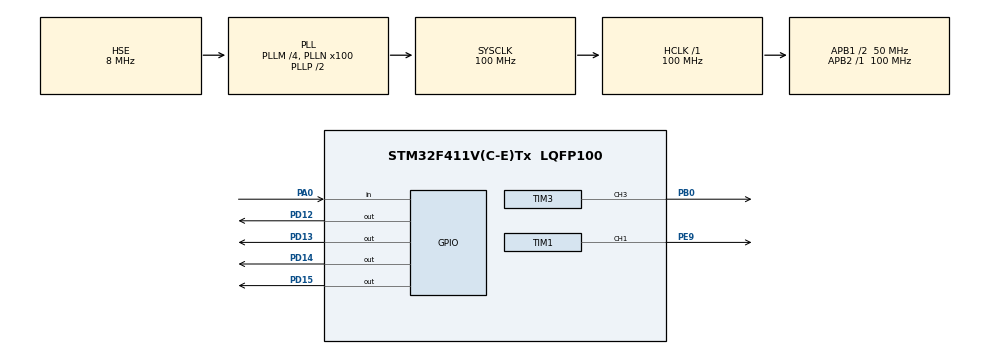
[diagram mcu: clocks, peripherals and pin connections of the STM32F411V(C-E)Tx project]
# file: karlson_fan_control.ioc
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Mcu.Family=STM32F4
Mcu.Name=STM32F411V(C-E)Tx
Mcu.Package=LQFP100
NVIC.PriorityGroup=NVIC_PRIORITYGROUP_4
NVIC.TIM1_BRK_TIM9_IRQn=true\:0\:0\:false\:false\:true\:true\:true
NVIC.TIM3_IRQn=true\:0\:0\:false\:false\:true\:true\:true
PA0-WKUP.GPIO_PuPd=GPIO_NOPULL
PA0-WKUP.Signal=GPIO_Input
PA13.Mode=Serial_Wire
PA13.Signal=SYS_JTMS-SWDIO
PA14.Mode=Serial_Wire
PA14.Signal=SYS_JTCK-SWCLK
PB0.GPIO_PuPd=GPIO_NOPULL
PB0.GPIO_Speed=GPIO_SPEED_FREQ_VERY_HIGH
PB0.Signal=S_TIM3_CH3
PD12.GPIO_Speed=GPIO_SPEED_FREQ_HIGH
PD12.Signal=GPIO_Output
PD13.GPIO_Speed=GPIO_SPEED_FREQ_HIGH
PD13.Signal=GPIO_Output
PD14.GPIO_Speed=GPIO_SPEED_FREQ_HIGH
PD14.Signal=GPIO_Output
PD15.GPIO_Speed=GPIO_SPEED_FREQ_HIGH
PD15.Signal=GPIO_Output
PE9.Signal=S_TIM1_CH1
PH0\ -\ OSC_IN.Mode=HSE-External-Oscillator
PH0\ -\ OSC_IN.Signal=RCC_OSC_IN
PH1\ -\ OSC_OUT.Mode=HSE-External-Oscillator
PH1\ -\ OSC_OUT.Signal=RCC_OSC_OUT
ProjectManager.HeapSize=0x200
ProjectManager.StackSize=0x400
ProjectManager.TargetToolchain=TrueSTUDIO
RCC.48MHZClocksFreq_Value=50000000
RCC.AHBFreq_Value=100000000
RCC.APB1CLKDivider=RCC_HCLK_DIV2
RCC.APB1Freq_Value=50000000
RCC.APB1TimFreq_Value=100000000
RCC.APB2Freq_Value=100000000
RCC.APB2TimFreq_Value=100000000
RCC.CortexFreq_Value=100000000
RCC.HCLKFreq_Value=100000000
RCC.HSE_VALUE=8000000
RCC.HSI_VALUE=16000000
RCC.LSE_VALUE=32768
RCC.PLLM=4
RCC.PLLN=100
RCC.PLLSourceVirtual=RCC_PLLSOURCE_HSE
RCC.SYSCLKFreq_VALUE=100000000
RCC.SYSCLKSource=RCC_SYSCLKSOURCE_PLLCLK
RCC.VCOOutputFreq_Value=200000000
SH.S_TIM1_CH1.0=TIM1_CH1,PWM Generation1 CH1
SH.S_TIM3_CH3.0=TIM3_CH3,PWM Generation3 CH3
TIM1.Channel-PWM\ Generation1\ CH1=TIM_CHANNEL_1
TIM1.OCMode_PWM-PWM\ Generation1\ CH1=TIM_OCMODE_PWM1
TIM1.OCPolarity_1=TIM_OCPOLARITY_HIGH
TIM1.Period=65535
TIM1.Prescaler=0
TIM1.Pulse-PWM\ Generation1\ CH1=0
TIM3.Channel-PWM\ Generation3\ CH3=TIM_CHANNEL_3
TIM3.OCMode_PWM-PWM\ Generation3\ CH3=TIM_OCMODE_PWM2
TIM3.Period=0
TIM3.Prescaler=0
VP_TIM3_VS_ClockSourceINT.Mode=Internal
board=custom

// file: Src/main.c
/* USER CODE BEGIN Header */
/**
  ******************************************************************************
  * @file           : main.c
  * @brief          : Main program body
  ******************************************************************************
  * @attention
  *
  * <h2><center>&copy; Copyright (c) 2019 STMicroelectronics.
  * All rights reserved.</center></h2>
  *
  * This software component is licensed by ST under BSD 3-Clause license,
  * the "License"; You may not use this file except in compliance with the
  * License. You may obtain a copy of the License at:
  *                        opensource.org/licenses/BSD-3-Clause
  *
  ******************************************************************************
  */
/* USER CODE END Header */

#include "main.h"

TIM_HandleTypeDef htim1;
TIM_HandleTypeDef htim3;

void SystemClock_Config(void);
static void MX_GPIO_Init(void);
static void MX_TIM3_Init(void);
static void MX_TIM1_Init(void);

int main(void)
{
  /* USER CODE BEGIN 1 */
	uint32_t i,d;
  /* USER CODE END 1 */

  /* MCU Configuration--------------------------------------------------------*/

  /* Reset of all peripherals, Initializes the Flash interface and the Systick. */
  HAL_Init();

  /* Configure the system clock */
  SystemClock_Config();

  /* Initialize all configured peripherals */
  MX_GPIO_Init();
  MX_TIM3_Init();
  MX_TIM1_Init();
  /* USER CODE BEGIN 2 */
  HAL_TIM_PWM_Start_IT(&htim3, TIM_CHANNEL_3);
  HAL_TIM_PWM_Start_IT(&htim1, TIM_CHANNEL_1);
  /* USER CODE END 2 */

  /* Infinite loop */
  while (1)
  {

    /* USER CODE BEGIN 3 */
	  // 10% duty cycle:     pulse_length = ((1999 + 1) * 10) / 100 - 1 = 199
	  // 20% duty cycle:     pulse_length = ((1999 + 1) * 20) / 100 - 1 = 399
	  // 30% duty cycle:     pulse_length = ((1999 + 1) * 30) / 100 - 1 = 599
	  // 40% duty cycle:     pulse_length = ((1999 + 1) * 40) / 100 - 1 = 799
	  // 50% duty cycle:     pulse_length = ((1999 + 1) * 50) / 100 - 1 = 999
	  // 60% duty cycle:     pulse_length = ((1999 + 1) * 60) / 100 - 1 = 1199
	  // 70% duty cycle:     pulse_length = ((1999 + 1) * 70) / 100 - 1 = 1399
	  // 80% duty cycle:     pulse_length = ((1999 + 1) * 80) / 100 - 1 = 1599
	  // 90% duty cycle:     pulse_length = ((1999 + 1) * 90) / 100 - 1 = 1799
	  // 100% duty cycle:     pulse_length = ((1999 + 1) * 100) / 100 - 1 = 1999

	  if (HAL_GPIO_ReadPin (GPIOA, GPIO_PIN_0))
	  {
		  /*HAL_Delay(50);*/
		  HAL_GPIO_WritePin(GPIOD, GPIO_PIN_12, GPIO_PIN_RESET);
		  HAL_GPIO_WritePin(GPIOD, GPIO_PIN_15, GPIO_PIN_SET);
		  TIM3->CCR3 = 3999; // PB0
		  // TIM1->CCR1 = 1999;  PE9
		  // __HAL_TIM_SET_COMPARE(&htim1, TIM_CHANNEL_1, 65535);
	  }
	  else
	  {
		  HAL_GPIO_WritePin(GPIOD, GPIO_PIN_12, GPIO_PIN_SET);
		  HAL_GPIO_WritePin(GPIOD, GPIO_PIN_15, GPIO_PIN_RESET);
		  TIM3->CCR3 = 0;
		  TIM1->CCR1 = 0;
	  }

  }
  /* USER CODE END 3 */
}

void SystemClock_Config(void)
{
  RCC_OscInitTypeDef RCC_OscInitStruct = {0};
  RCC_ClkInitTypeDef RCC_ClkInitStruct = {0};

  /** Configure the main internal regulator output voltage
  */
  __HAL_RCC_PWR_CLK_ENABLE();
  __HAL_PWR_VOLTAGESCALING_CONFIG(PWR_REGULATOR_VOLTAGE_SCALE1);
  /** Initializes the CPU, AHB and APB busses clocks
  */
  RCC_OscInitStruct.OscillatorType = RCC_OSCILLATORTYPE_HSE;
  RCC_OscInitStruct.HSEState = RCC_HSE_ON;
  RCC_OscInitStruct.PLL.PLLState = RCC_PLL_ON;
  RCC_OscInitStruct.PLL.PLLSource = RCC_PLLSOURCE_HSE;
  RCC_OscInitStruct.PLL.PLLM = 4;
  RCC_OscInitStruct.PLL.PLLN = 100;
  RCC_OscInitStruct.PLL.PLLP = RCC_PLLP_DIV2;
  RCC_OscInitStruct.PLL.PLLQ = 4;
  if (HAL_RCC_OscConfig(&RCC_OscInitStruct) != HAL_OK)
  {
    Error_Handler();
  }
  /** Initializes the CPU, AHB and APB busses clocks
  */
  RCC_ClkInitStruct.ClockType = RCC_CLOCKTYPE_HCLK|RCC_CLOCKTYPE_SYSCLK
                              |RCC_CLOCKTYPE_PCLK1|RCC_CLOCKTYPE_PCLK2;
  RCC_ClkInitStruct.SYSCLKSource = RCC_SYSCLKSOURCE_PLLCLK;
  RCC_ClkInitStruct.AHBCLKDivider = RCC_SYSCLK_DIV1;
  RCC_ClkInitStruct.APB1CLKDivider = RCC_HCLK_DIV2;
  RCC_ClkInitStruct.APB2CLKDivider = RCC_HCLK_DIV1;

  if (HAL_RCC_ClockConfig(&RCC_ClkInitStruct, FLASH_LATENCY_3) != HAL_OK)
  {
    Error_Handler();
  }
}

static void MX_TIM1_Init(void)
{

  TIM_MasterConfigTypeDef sMasterConfig = {0};
  TIM_OC_InitTypeDef sConfigOC = {0};
  TIM_BreakDeadTimeConfigTypeDef sBreakDeadTimeConfig = {0};

  htim1.Instance = TIM1;
  htim1.Init.Prescaler = 0;
  htim1.Init.CounterMode = TIM_COUNTERMODE_UP;
  htim1.Init.Period = 65535;
  htim1.Init.ClockDivision = TIM_CLOCKDIVISION_DIV1;
  htim1.Init.RepetitionCounter = 0;
  htim1.Init.AutoReloadPreload = TIM_AUTORELOAD_PRELOAD_DISABLE;
  if (HAL_TIM_PWM_Init(&htim1) != HAL_OK)
  {
    Error_Handler();
  }
  sMasterConfig.MasterOutputTrigger = TIM_TRGO_RESET;
  sMasterConfig.MasterSlaveMode = TIM_MASTERSLAVEMODE_DISABLE;
  if (HAL_TIMEx_MasterConfigSynchronization(&htim1, &sMasterConfig) != HAL_OK)
  {
    Error_Handler();
  }
  sConfigOC.OCMode = TIM_OCMODE_PWM1;
  sConfigOC.Pulse = 0;
  sConfigOC.OCPolarity = TIM_OCPOLARITY_HIGH;
  sConfigOC.OCNPolarity = TIM_OCNPOLARITY_HIGH;
  sConfigOC.OCFastMode = TIM_OCFAST_DISABLE;
  sConfigOC.OCIdleState = TIM_OCIDLESTATE_RESET;
  sConfigOC.OCNIdleState = TIM_OCNIDLESTATE_RESET;
  if (HAL_TIM_PWM_ConfigChannel(&htim1, &sConfigOC, TIM_CHANNEL_1) != HAL_OK)
  {
    Error_Handler();
  }
  sBreakDeadTimeConfig.OffStateRunMode = TIM_OSSR_DISABLE;
  sBreakDeadTimeConfig.OffStateIDLEMode = TIM_OSSI_DISABLE;
  sBreakDeadTimeConfig.LockLevel = TIM_LOCKLEVEL_OFF;
  sBreakDeadTimeConfig.DeadTime = 0;
  sBreakDeadTimeConfig.BreakState = TIM_BREAK_DISABLE;
  sBreakDeadTimeConfig.BreakPolarity = TIM_BREAKPOLARITY_HIGH;
  sBreakDeadTimeConfig.AutomaticOutput = TIM_AUTOMATICOUTPUT_DISABLE;
  if (HAL_TIMEx_ConfigBreakDeadTime(&htim1, &sBreakDeadTimeConfig) != HAL_OK)
  {
    Error_Handler();
  }
  HAL_TIM_MspPostInit(&htim1);

}

static void MX_TIM3_Init(void)
{

  TIM_ClockConfigTypeDef sClockSourceConfig = {0};
  TIM_MasterConfigTypeDef sMasterConfig = {0};
  TIM_OC_InitTypeDef sConfigOC = {0};

  htim3.Instance = TIM3;
  htim3.Init.Prescaler = 0;
  htim3.Init.CounterMode = TIM_COUNTERMODE_UP;
  htim3.Init.Period = 0;
  htim3.Init.ClockDivision = TIM_CLOCKDIVISION_DIV1;
  htim3.Init.AutoReloadPreload = TIM_AUTORELOAD_PRELOAD_DISABLE;
  if (HAL_TIM_Base_Init(&htim3) != HAL_OK)
  {
    Error_Handler();
  }
  sClockSourceConfig.ClockSource = TIM_CLOCKSOURCE_INTERNAL;
  if (HAL_TIM_ConfigClockSource(&htim3, &sClockSourceConfig) != HAL_OK)
  {
    Error_Handler();
  }
  if (HAL_TIM_PWM_Init(&htim3) != HAL_OK)
  {
    Error_Handler();
  }
  sMasterConfig.MasterOutputTrigger = TIM_TRGO_RESET;
  sMasterConfig.MasterSlaveMode = TIM_MASTERSLAVEMODE_DISABLE;
  if (HAL_TIMEx_MasterConfigSynchronization(&htim3, &sMasterConfig) != HAL_OK)
  {
    Error_Handler();
  }
  sConfigOC.OCMode = TIM_OCMODE_PWM2;
  sConfigOC.Pulse = 0;
  sConfigOC.OCPolarity = TIM_OCPOLARITY_HIGH;
  sConfigOC.OCFastMode = TIM_OCFAST_DISABLE;
  if (HAL_TIM_PWM_ConfigChannel(&htim3, &sConfigOC, TIM_CHANNEL_3) != HAL_OK)
  {
    Error_Handler();
  }
  HAL_TIM_MspPostInit(&htim3);

}

static void MX_GPIO_Init(void)
{
  GPIO_InitTypeDef GPIO_InitStruct = {0};

  /* GPIO Ports Clock Enable */
  __HAL_RCC_GPIOH_CLK_ENABLE();
  __HAL_RCC_GPIOA_CLK_ENABLE();
  __HAL_RCC_GPIOB_CLK_ENABLE();
  __HAL_RCC_GPIOE_CLK_ENABLE();
  __HAL_RCC_GPIOD_CLK_ENABLE();

  /*Configure GPIO pin Output Level */
  HAL_GPIO_WritePin(GPIOD, GPIO_PIN_12|GPIO_PIN_13|GPIO_PIN_14|GPIO_PIN_15, GPIO_PIN_RESET);

  /*Configure GPIO pin : PA0 */
  GPIO_InitStruct.Pin = GPIO_PIN_0;
  GPIO_InitStruct.Mode = GPIO_MODE_INPUT;
  GPIO_InitStruct.Pull = GPIO_NOPULL;
  HAL_GPIO_Init(GPIOA, &GPIO_InitStruct);

  /*Configure GPIO pins : PD12 PD13 PD14 PD15 */
  GPIO_InitStruct.Pin = GPIO_PIN_12|GPIO_PIN_13|GPIO_PIN_14|GPIO_PIN_15;
  GPIO_InitStruct.Mode = GPIO_MODE_OUTPUT_PP;
  GPIO_InitStruct.Pull = GPIO_NOPULL;
  GPIO_InitStruct.Speed = GPIO_SPEED_FREQ_HIGH;
  HAL_GPIO_Init(GPIOD, &GPIO_InitStruct);

}

void Error_Handler(void)
{
}

/************************ (C) COPYRIGHT STMicroelectronics *****END OF FILE****/
